# CY8C4245LQI_483 register map
File version: 0.1
PSoC 4200
Registers are 32-bit, read-write, no defined reset value unless marked. A register's access mark holds for its fields unless they carry their own. Offsets are from the block's base; lines under a group give offsets from that group; [hi:lo] are bit positions; {n}, {i} and the like mark numbered series; 'fields as' and 'values as' point back to an identical list; <NAME> marks a mode.

## Memory map
0x00000000 IDAC_2 — IDAC
0x00000000 PWM_DAC
0x00000000 Timer_Tick
0x00000000 Control_PWM
0x00000000 Timer_1
0x00000000 PWM_M
0x00000000 EZI2C_CAM — Serial Communication Block
0x00000000 I2C_LED — Serial Communication Block
0x00000000 STEP_COUNT
0x00000000 IDAC_1 — IDAC
0x00000000 Comp_ISENSE — Comparator

## IDAC_2 — IDAC
Base 0x00000000
Same registers: IDAC_1 0x00000000
0x40080004 CSD_IDAC_POLARITY
0x40080008 CSD_IDAC
0x4008FF00 CSD_TRIM1 — CSD IDAC TRIM1
0x4008FF04 CSD_TRIM2 — CSD IDAC TRIM2

## PWM_DAC
Base 0x00000000
0x40050188 COUNTER — Current counter value
0x4005018C CC — Compare / capture value
0x40050190 CC_BUF — Compare / capture buffer value
0x40050194 PERIOD — Period value
0x40050198 PERIOD_BUF — Period buffer value

## Timer_Tick
Base 0x00000000
0x40050108 COUNTER — Current counter value
0x4005010C CC — Compare / capture value
0x40050110 CC_BUF — Compare / capture buffer value
0x40050114 PERIOD — Period value
0x40050118 PERIOD_BUF — Period buffer value

## Control_PWM
Base 0x00000000
0x400F0073 Control_PWM_CONTROL_REG 8-bit

## Timer_1
Base 0x00000000
0x400501C8 COUNTER — Current counter value
0x400501CC CC — Compare / capture value
0x400501D0 CC_BUF — Compare / capture buffer value
0x400501D4 PERIOD — Period value
0x400501D8 PERIOD_BUF — Period buffer value

## PWM_M
Base 0x00000000
0x400F0023 PWM_M__COMPARE1 8-bit — UDB.D0 - Assigned Compare1 Value
0x400F0033 PWM_M__COMPARE2 8-bit — UDB.D1 - Assigned Compare2 Value
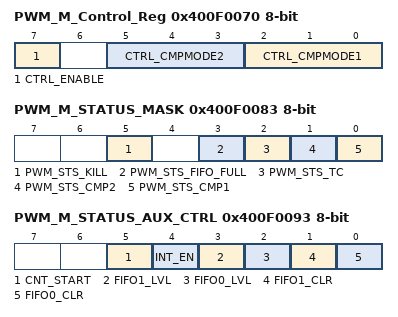
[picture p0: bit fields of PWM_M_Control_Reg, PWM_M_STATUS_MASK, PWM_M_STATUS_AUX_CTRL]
0x400F0070 PWM_M_Control_Reg 8-bit — UDB Control Register - Assigned Control Register Value
  [7] CTRL_ENABLE — Enable the PWM
  [5:3] CTRL_CMPMODE2 — Compare mode 2
  [2:0] CTRL_CMPMODE1 — Compare mode 1
0x400F0083 PWM_M_STATUS_MASK 8-bit — UDB Status bits Interrupt Mask Enable Register
  [5] PWM_STS_KILL ro — Enables the Interrupt on Kill
  [3] PWM_STS_FIFO_FULL ro — FIFO Full Status Mask
  [2] PWM_STS_TC ro — Enables the Interrupt on Terminal Count
  [1] PWM_STS_CMP2 ro — Enables the Interrupt on Compare 2
  [0] PWM_STS_CMP1 ro — Enables the Interrupt on Compare 1
0x400F0093 PWM_M_STATUS_AUX_CTRL 8-bit — UDB Auxilliary Control Register
  [5] CNT_START — FIFO0 clear
    0=E_CNT_START0 (Disable counter); 1=E_CNT_START1 (Enable counter)
  [4] INT_EN
    0=E_INT_EN0 (Interrupt disabled); 1=E_INT_EN1 (Interrupt enabled)
  [3] FIFO1_LVL — FIFO level
    0=E_FIFO_LVL_0 (FIFO LVL: input mode: FIFO not full; output mode: FIFO not empty); 1=E_FIFO_LVL_1 (FIFO LVL: input mode: FIFO at least 1/2 empty; output mode: FIFO at least 1/2 full)
  [2] FIFO0_LVL — FIFO level
    values as FIFO1_LVL
  [1] FIFO1_CLR — FIFO1 clear
    0=E_FIFO_CLR_0 (Normal FIFO operation); 1=E_FIFO_CLR_1 (Clear FIFO state)
  [0] FIFO0_CLR — FIFO0 clear
    values as FIFO1_CLR

## STEP_COUNT
Base 0x00000000
0x40050148 COUNTER — Current counter value
0x4005014C CC — Compare / capture value
0x40050150 CC_BUF — Compare / capture buffer value
0x40050154 PERIOD — Period value
0x40050158 PERIOD_BUF — Period buffer value

## Comp_ISENSE — Comparator
Base 0x00000000
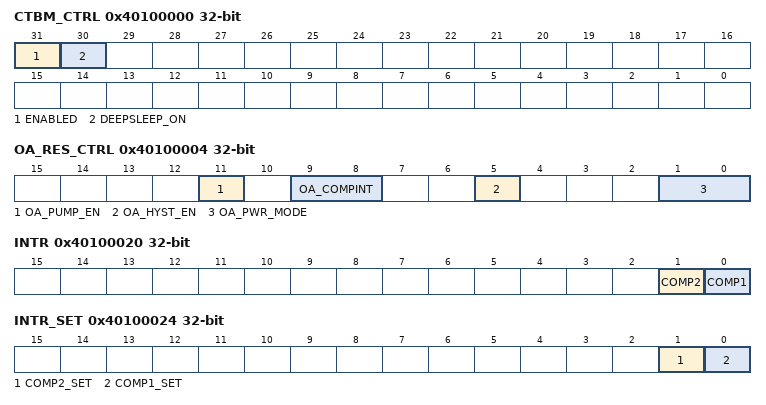
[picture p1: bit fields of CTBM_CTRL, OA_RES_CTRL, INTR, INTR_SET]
0x40100000 CTBM_CTRL — Global CTB IP and power control
  [31] ENABLED — Selects component behavior in DeepSleep power mode
    0=DISABLE (CTB IP disabled (put analog in power down, open all switches)); 1=ENABLE (CTB IP enabledCTB IP enabled)
  [30] DEEPSLEEP_ON — Selects component behavior in DeepSleep power mode
    0=DISABLE (CTB IP disabled off during DeepSleep power mode); 1=ENABLE (CTB IP remains enabled during DeepSleep power mode (if ENABLED=1))
0x40100004 OA_RES_CTRL — Comparator and resistor control
  [11] OA_PUMP_EN — Selects pump
    0=DISABLE (Pump disabled); 1=ENABLE (Pump enabled)
  [9:8] OA_COMPINT — Selects comparator edge detect
    0=DISABLE (Disabled); 1=RISING (Rising edge); 2=FALLING (Falling edge); 3=BOTH (Both rising and falling edges)
  [5] OA_HYST_EN — Selects hysteresis (10mV)
    0=DISABLE (Hysteresis disabled); 1=ENABLE (Hysteresis enabled)
  [1:0] OA_PWR_MODE — Selects speed for comparator
    0=OFF; 1=SLOW (Slow speed); 2=MED (Medium speed); 3=FAST (Fast speed)
0x4010000C COMP_STAT — Comparator status
  [16] OA_COMP ro — Current comparator status
0x40100020 INTR — Interrupt request register
  [1] COMP2 — Comparator #2 Interrupt: hardware sets this interrupt when comparator 0 triggers. Write with '1' to clear bit.
  [0] COMP1 — Comparator #1 Interrupt: hardware sets this interrupt when comparator 0 triggers. Write with '1' to clear bit.
0x40100024 INTR_SET — Interrupt request set register
  [1] COMP2_SET — Write with '1' to set corresponding bit in interrupt request register.
  [0] COMP1_SET — Write with '1' to set corresponding bit in interrupt request register.
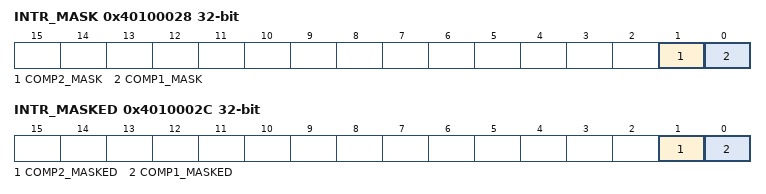
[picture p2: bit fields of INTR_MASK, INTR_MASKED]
0x40100028 INTR_MASK — Interrupt request mask
  [1] COMP2_MASK — Mask bit for corresponding bit in interrupt request register.
  [0] COMP1_MASK — Mask bit for corresponding bit in interrupt request register.
0x4010002C INTR_MASKED — Interrupt request masked
  [1] COMP2_MASKED ro — Logical and of corresponding request and mask bits.
  [0] COMP1_MASKED ro — Logical and of corresponding request and mask bits.
0x40100F00 OA_OFFSET_TRIM — Comparator offset trim
0x40100F04 OA_SLOPE_OFFSET_TRIM — Comparator slope offset drift trim
0x40100F08 OA_COMP_TRIM — Comparator trim
